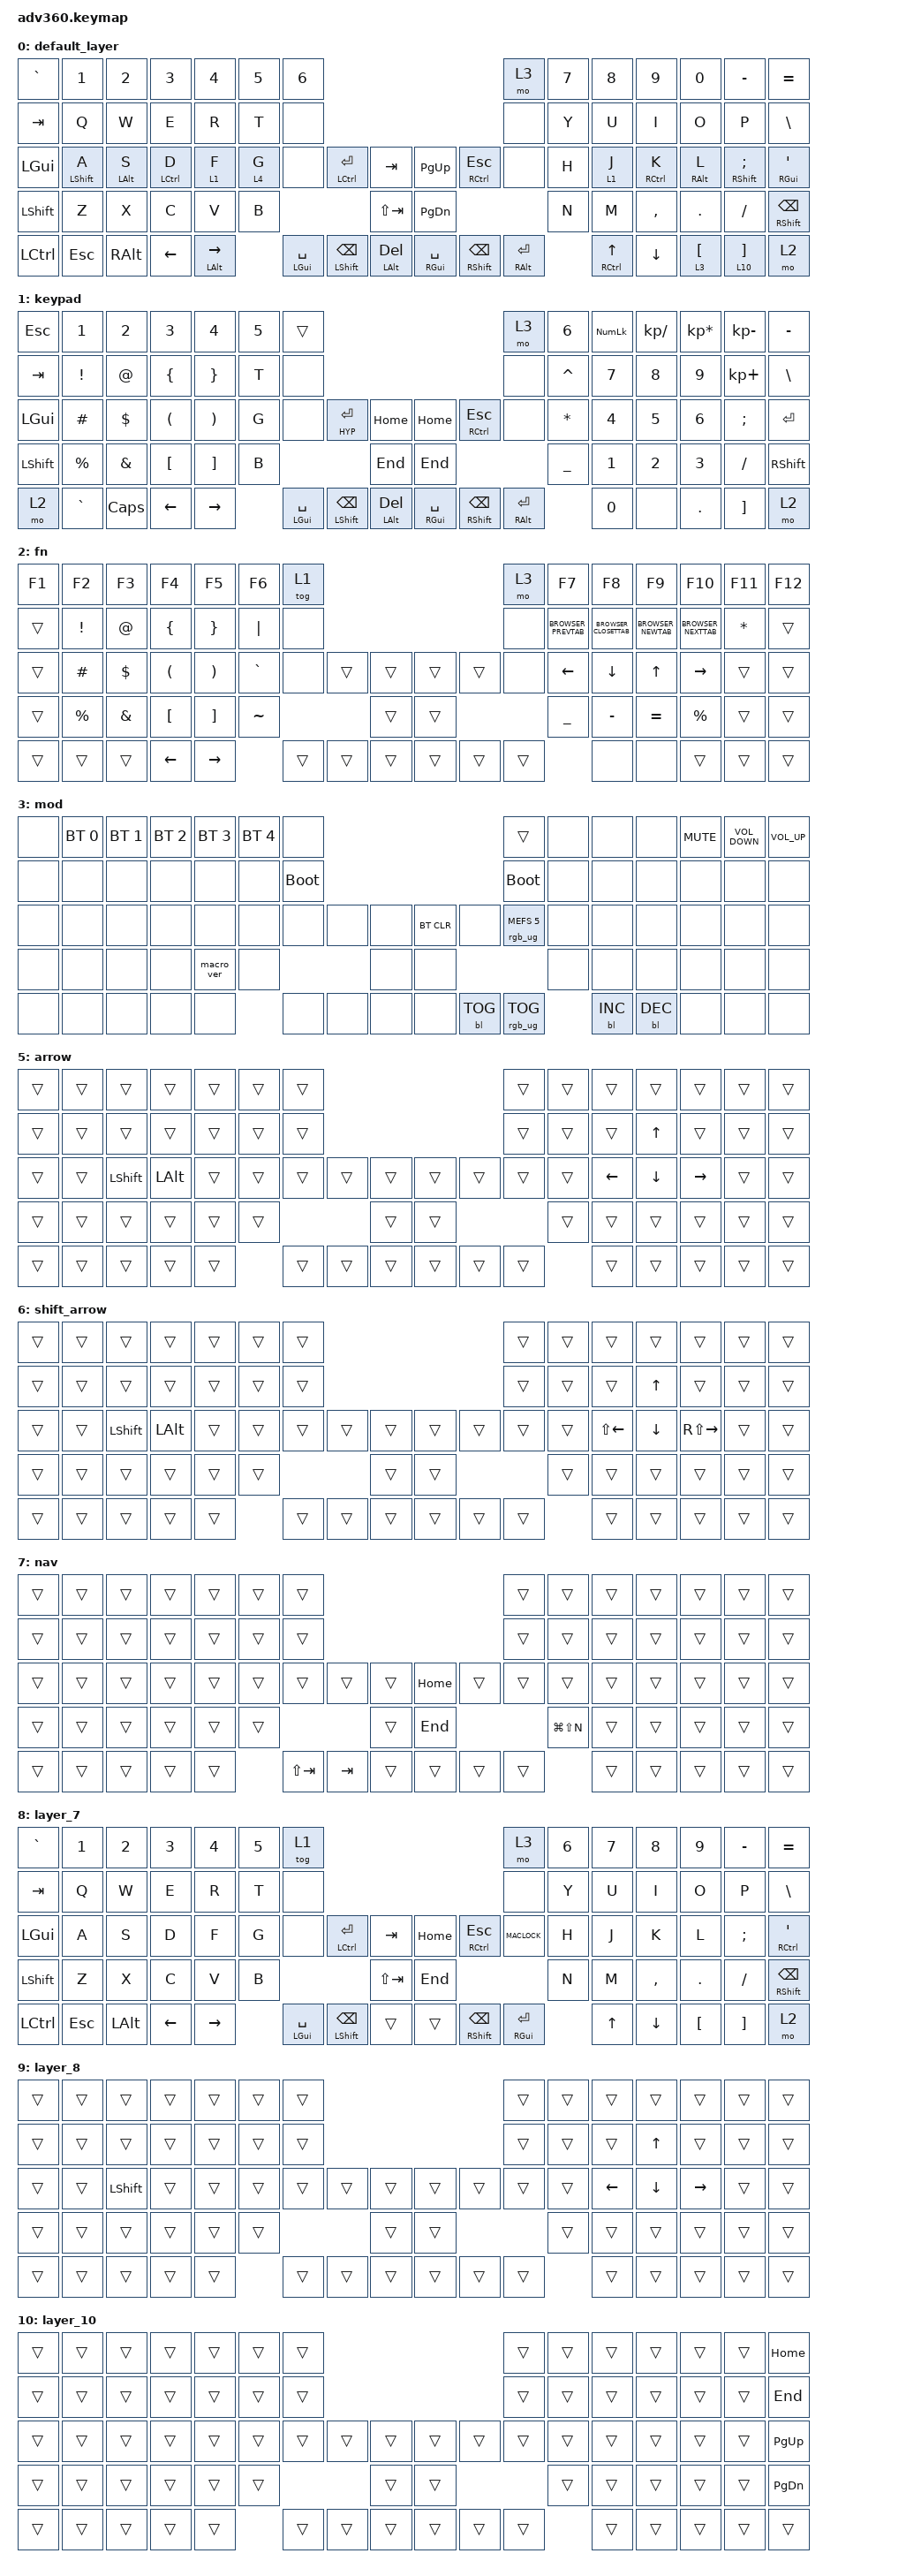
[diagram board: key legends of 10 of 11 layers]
#include <dt-bindings/zmk/mouse.h>
#include <behaviors.dtsi>
#include <dt-bindings/zmk/backlight.h>
#include <dt-bindings/zmk/bt.h>
#include <dt-bindings/zmk/keys.h>
#include <dt-bindings/zmk/pointing.h>
#include <dt-bindings/zmk/rgb.h>

#define HYP LS(LC(LA(LGUI)))
#define HYPER    LS(LC(LA(LGUI)))
#define MACLOCK  LG(LC(Q))
#define BROWSER_SEARCH LG(F)
#define BROWSER_NEWTAB LG(T)
#define BROWSER_CLOSETTAB LG(W)
#define BROWSER_NEXTTAB LG(LA(RIGHT))
#define BROWSER_PREVTAB LG(LA(LEFT))

&mt {
    tapping-term-ms = <210>;
    quick_tap_ms = <200>;
    flavor = "tap-preferred";
};

&lt { quick_tap_ms = <200>; };

/ {
    behaviors {
        #include "macros.dtsi"
      #include "version.dtsi"
      #ifndef VERSION_MACRO

        macro_ver: macro_ver {
            compatible = "zmk,behavior-macro";
            label = "macro_version";
            #binding-cells = <0>;
            bindings = <&kp RET>;
        };

        #endif

        lm: lm {
            compatible = "zmk,behavior-macro-two-param";
            wait-ms = <0>;
            tap-ms = <0>;
            #binding-cells = <2>;
            bindings =
                <&macro_param_1to1>,
                <&macro_press>,
                <&mo MACRO_PLACEHOLDER &macro_param_2to1>,
                <&macro_press>,
                <&kp MACRO_PLACEHOLDER>,
                <&macro_pause_for_release>,
                <&macro_param_2to1>,
                <&macro_release>,
                <&kp MACRO_PLACEHOLDER &macro_param_1to1>,
                <&macro_release>,
                <&mo MACRO_PLACEHOLDER>;
        };

        hm: homerow_mods {
            compatible = "zmk,behavior-hold-tap";
            label = "HOMEROW_MODS";
            #binding-cells = <2>;
            tapping-term-ms = <200>;
            quick_tap_ms = <175>;
            flavor = "tap-preferred";
            bindings = <&kp>, <&kp>;
        };
    };

    combos {
        compatible = "zmk,combos";

        escape {
            bindings = <&kp ESCAPE>;
            key-positions = <0 1>;
        };

        backspace {
            bindings = <&kp BACKSPACE>;
            key-positions = <12 13>;
        };
    };

    macros {
    };

    keymap {
        compatible = "zmk,keymap";

        default_layer {
            bindings = <
&kp GRAVE  &kp N1       &kp N2         &kp N3       &kp N4          &kp N5   &kp N6                                                                                         &mo 3           &kp N7  &kp N8        &kp N9       &kp N0      &kp MINUS             &kp EQUAL
&kp TAB    &kp Q        &kp W          &kp E        &kp R           &kp T    &none                                                                                          &none           &kp Y   &kp U         &kp I        &kp O       &kp P                 &kp BSLH
&kp LGUI   &mt LSHFT A  &mt LALT S     &mt LCTRL D  &lt 1 F         &lt 4 G  &none           &mt LCTRL ENTER      &kp TAB              &kp PG_UP       &mt RCTRL ESC        &none           &kp H   &lt 1 J       &mt RCTRL K  &mt RALT L  &mt RSHFT SEMI        &mt RGUI SQT
&kp LSHFT  &kp Z        &kp X          &kp C        &kp V           &kp B                                         &kp LS(TAB)          &kp PG_DN                                            &kp N   &kp M         &kp COMMA    &kp DOT     &kp FSLH              &mt RSHFT BACKSPACE
&kp LCTRL  &kp ESC      &kp RIGHT_ALT  &kp LEFT     &mt LALT RIGHT           &mt LGUI SPACE  &mt LSHFT BACKSPACE  &mt LALT DELETE      &mt RGUI SPACE  &mt RSHFT BACKSPACE  &mt RALT ENTER          &mt RCTRL UP  &kp DOWN     &lt 3 LBKT  &lt 10 RIGHT_BRACKET  &mo 2
            >;
        };

        keypad {
            bindings = <
&kp ESC    &kp N1       &kp N2      &kp N3    &kp N4     &kp N5  &trans                                                                                         &mo 3           &kp N6          &kp KP_NUM  &kp KP_DIVIDE  &kp KP_MULTIPLY  &kp KP_MINUS  &kp MINUS
&kp TAB    &kp EXCL     &kp AT      &kp LBRC  &kp RBRC   &kp T   &none                                                                                          &none           &kp CARET       &kp N7      &kp N8         &kp N9           &kp KP_PLUS   &kp BSLH
&kp LGUI   &kp HASH     &kp DOLLAR  &kp LPAR  &kp RPAR   &kp G   &none           &mt HYP ENTER        &kp HOME             &kp HOME        &mt RCTRL ESC        &none           &kp STAR        &kp N4      &kp N5         &kp N6           &kp SEMI      &kp ENTER
&kp LSHFT  &kp PERCENT  &kp AMPS    &kp LBKT  &kp RBKT   &kp B                                        &kp END              &kp END                                              &kp UNDERSCORE  &kp N1      &kp N2         &kp N3           &kp FSLH      &kp RSHFT
&mo 2      &kp GRAVE    &kp CAPS    &kp LEFT  &kp RIGHT          &mt LGUI SPACE  &mt LSHFT BACKSPACE  &mt LALT DELETE      &mt RGUI SPACE  &mt RSHFT BACKSPACE  &mt RALT ENTER                  &kp N0      &none          &kp DOT          &kp RBKT      &mo 2
            >;
        };

        fn {
            bindings = <
&kp F1  &kp F2       &kp F3      &kp F4    &kp F5     &kp F6     &tog 1                                      &mo 3   &kp F7               &kp F8                 &kp F9              &kp F10              &kp F11       &kp F12
&trans  &kp EXCL     &kp AT      &kp LBRC  &kp RBRC   &kp PIPE   &none                                       &none   &kp BROWSER_PREVTAB  &kp BROWSER_CLOSETTAB  &kp BROWSER_NEWTAB  &kp BROWSER_NEXTTAB  &kp ASTERISK  &trans
&trans  &kp HASH     &kp DOLLAR  &kp LPAR  &kp RPAR   &kp GRAVE  &none   &trans  &trans      &trans  &trans  &none   &kp LEFT             &kp DOWN               &kp UP              &kp RIGHT            &trans        &trans
&trans  &kp PERCENT  &kp AMPS    &kp LBKT  &kp RBKT   &kp TILDE                  &trans      &trans                  &kp UNDER            &kp MINUS              &kp EQUAL           &kp PERCENT          &trans        &trans
&trans  &trans       &trans      &kp LEFT  &kp RIGHT             &trans  &trans  &trans      &trans  &trans  &trans                       &none                  &none               &trans               &trans        &trans
            >;
        };

        mod {
            bindings = <
&none  &bt BT_SEL 0  &bt BT_SEL 1  &bt BT_SEL 2  &bt BT_SEL 3  &bt BT_SEL 4  &none                                                  &trans                  &none  &none       &none       &kp K_MUTE  &kp K_VOLUME_DOWN  &kp K_VOL_UP
&none  &none         &none         &none         &none         &none         &bootloader                                            &bootloader             &none  &none       &none       &none       &none              &none
&none  &none         &none         &none         &none         &none         &none        &none  &none      &bt BT_CLR  &none       &rgb_ug RGB_MEFS_CMD 5  &none  &none       &none       &none       &none              &none
&none  &none         &none         &none         &macro_ver    &none                             &none      &none                                           &none  &none       &none       &none       &none              &none
&none  &none         &none         &none         &none                       &none        &none  &none      &none       &bl BL_TOG  &rgb_ug RGB_TOG                &bl BL_INC  &bl BL_DEC  &none       &none              &none
            >;
        };

        alt_arrow {
            bindings = <
&trans  &trans  &trans  &trans  &trans  &trans  &trans                                                &trans     &trans  &trans             &trans             &trans             &trans  &trans
&trans  &trans  &trans  &trans  &trans  &trans  &trans                                                &trans     &trans  &trans             &kp RA(RS(RC(I)))  &trans             &trans  &trans
&trans  &trans  &trans  &trans  &trans  &trans  &trans         &trans  &trans      &trans  &trans     &trans     &trans  &kp RS(RA(RC(J)))  &kp RS(RA(RC(K)))  &kp RS(RA(RC(L)))  &trans  &trans
&trans  &trans  &trans  &trans  &trans  &trans                         &trans      &trans                        &trans  &trans             &trans             &trans             &trans  &trans
&trans  &trans  &trans  &trans  &trans          &kp RIGHT_GUI  &trans  &trans      &trans  &mkp RCLK  &mkp LCLK          &trans             &trans             &trans             &trans  &trans
            >;
        };

        arrow {
            bindings = <
&trans  &trans  &trans     &trans    &trans  &trans  &trans                                      &trans  &trans  &trans          &trans          &trans           &trans  &trans
&trans  &trans  &trans     &trans    &trans  &trans  &trans                                      &trans  &trans  &trans          &kp UP_ARROW    &trans           &trans  &trans
&trans  &trans  &kp LSHFT  &kp LALT  &trans  &trans  &trans  &trans  &trans      &trans  &trans  &trans  &trans  &kp LEFT_ARROW  &kp DOWN_ARROW  &kp RIGHT_ARROW  &trans  &trans
&trans  &trans  &trans     &trans    &trans  &trans                  &trans      &trans                  &trans  &trans          &trans          &trans           &trans  &trans
&trans  &trans  &trans     &trans    &trans          &trans  &trans  &trans      &trans  &trans  &trans          &trans          &trans          &trans           &trans  &trans
            >;
        };

        shift_arrow {
            bindings = <
&trans  &trans  &trans     &trans    &trans  &trans  &trans                                      &trans  &trans  &trans              &trans          &trans               &trans  &trans
&trans  &trans  &trans     &trans    &trans  &trans  &trans                                      &trans  &trans  &trans              &kp UP_ARROW    &trans               &trans  &trans
&trans  &trans  &kp LSHFT  &kp LALT  &trans  &trans  &trans  &trans  &trans      &trans  &trans  &trans  &trans  &kp LS(LEFT_ARROW)  &kp DOWN_ARROW  &kp RS(RIGHT_ARROW)  &trans  &trans
&trans  &trans  &trans     &trans    &trans  &trans                  &trans      &trans                  &trans  &trans              &trans          &trans               &trans  &trans
&trans  &trans  &trans     &trans    &trans          &trans  &trans  &trans      &trans  &trans  &trans          &trans              &trans          &trans               &trans  &trans
            >;
        };

        nav {
            bindings = <
&trans  &trans  &trans  &trans  &trans  &trans  &trans                                              &trans  &trans         &trans  &trans  &trans  &trans  &trans
&trans  &trans  &trans  &trans  &trans  &trans  &trans                                              &trans  &trans         &trans  &trans  &trans  &trans  &trans
&trans  &trans  &trans  &trans  &trans  &trans  &trans       &trans   &trans      &kp HOME  &trans  &trans  &trans         &trans  &trans  &trans  &trans  &trans
&trans  &trans  &trans  &trans  &trans  &trans                        &trans      &kp END                   &kp LG(LS(N))  &trans  &trans  &trans  &trans  &trans
&trans  &trans  &trans  &trans  &trans          &kp LS(TAB)  &kp TAB  &trans      &trans    &trans  &trans                 &trans  &trans  &trans  &trans  &trans
            >;
        };

        layer_7 {
            bindings = <
&kp GRAVE  &kp N1   &kp N2    &kp N3    &kp N4     &kp N5  &tog 1                                                                                &mo 3           &kp N6  &kp N7  &kp N8     &kp N9    &kp MINUS  &kp EQUAL
&kp TAB    &kp Q    &kp W     &kp E     &kp R      &kp T   &none                                                                                 &none           &kp Y   &kp U   &kp I      &kp O     &kp P      &kp BSLH
&kp LGUI   &kp A    &kp S     &kp D     &kp F      &kp G   &none           &mt LCTRL ENTER       &kp TAB          &kp HOME  &mt RCTRL ESC        &kp MACLOCK     &kp H   &kp J   &kp K      &kp L     &kp SEMI   &mt RCTRL SQT
&kp LSHFT  &kp Z    &kp X     &kp C     &kp V      &kp B                                         &kp LS(TAB)      &kp END                                        &kp N   &kp M   &kp COMMA  &kp DOT   &kp FSLH   &mt RSHFT BACKSPACE
&kp LCTRL  &kp ESC  &kp LALT  &kp LEFT  &kp RIGHT          &mt LGUI SPACE  &mt LSHIFT BACKSPACE  &trans           &trans    &mt RSHFT BACKSPACE  &mt RGUI ENTER          &kp UP  &kp DOWN   &kp LBKT  &kp RBKT   &mo 2
            >;
        };

        layer_8 {
            bindings = <
&trans  &trans  &trans     &trans  &trans  &trans  &trans                                      &trans  &trans  &trans          &trans          &trans           &trans  &trans
&trans  &trans  &trans     &trans  &trans  &trans  &trans                                      &trans  &trans  &trans          &kp UP_ARROW    &trans           &trans  &trans
&trans  &trans  &kp LSHFT  &trans  &trans  &trans  &trans  &trans  &trans      &trans  &trans  &trans  &trans  &kp LEFT_ARROW  &kp DOWN_ARROW  &kp RIGHT_ARROW  &trans  &trans
&trans  &trans  &trans     &trans  &trans  &trans                  &trans      &trans                  &trans  &trans          &trans          &trans           &trans  &trans
&trans  &trans  &trans     &trans  &trans          &trans  &trans  &trans      &trans  &trans  &trans          &trans          &trans          &trans           &trans  &trans
            >;
        };

        layer_10 {
            bindings = <
&trans  &trans  &trans  &trans  &trans  &trans  &trans                                      &trans  &trans  &trans  &trans  &trans  &trans  &kp HOME
&trans  &trans  &trans  &trans  &trans  &trans  &trans                                      &trans  &trans  &trans  &trans  &trans  &trans  &kp END
&trans  &trans  &trans  &trans  &trans  &trans  &trans  &trans  &trans      &trans  &trans  &trans  &trans  &trans  &trans  &trans  &trans  &kp PAGE_UP
&trans  &trans  &trans  &trans  &trans  &trans                  &trans      &trans                  &trans  &trans  &trans  &trans  &trans  &kp PAGE_DOWN
&trans  &trans  &trans  &trans  &trans          &trans  &trans  &trans      &trans  &trans  &trans          &trans  &trans  &trans  &trans  &trans
            >;
        };
    };
};
